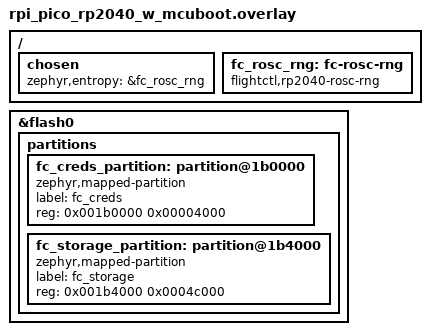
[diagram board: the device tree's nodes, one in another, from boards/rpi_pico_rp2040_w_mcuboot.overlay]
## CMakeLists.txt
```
# flightctl-mcu on Zephyr: the agent core, the Zephyr port and a small
# application. Built with zephyr/build.sh.
cmake_minimum_required(VERSION 3.20)
find_package(Zephyr REQUIRED HINTS $ENV{ZEPHYR_BASE})
project(flightctl_mcu)
# For mbedTLS too: it includes fc-mbedtls-user.h (prj.conf).
zephyr_include_directories(include)

set(ROOT ${CMAKE_CURRENT_LIST_DIR}/..)

# WAMR (third_party/fetch-wamr.sh): fast interpreter only, as in the other
# builds.
enable_language(ASM)
set(WAMR_BUILD_PLATFORM "zephyr")
if(CONFIG_ARCH_POSIX)
    if(CMAKE_HOST_SYSTEM_PROCESSOR MATCHES "^(arm64|aarch64)")
        set(WAMR_BUILD_TARGET "AARCH64")
    else()
        set(WAMR_BUILD_TARGET "X86_64")
    endif()
elseif(CONFIG_CPU_CORTEX_M0PLUS OR CONFIG_CPU_CORTEX_M0)
    set(WAMR_BUILD_TARGET "THUMBV6M")
elseif(CONFIG_CPU_CORTEX_M)
    set(WAMR_BUILD_TARGET "THUMBV7EM")
elseif(CONFIG_XTENSA)
    set(WAMR_BUILD_TARGET "XTENSA")
else()
    message(FATAL_ERROR "flightctl-mcu: no WAMR target for this board yet")
endif()
set(WAMR_BUILD_INTERP 1)
set(WAMR_BUILD_FAST_INTERP 1)
set(WAMR_BUILD_AOT 0)
set(WAMR_BUILD_JIT 0)
set(WAMR_BUILD_LIBC_BUILTIN 0)
set(WAMR_BUILD_LIBC_WASI 0)
set(WAMR_BUILD_SIMD 0)
set(WAMR_BUILD_REF_TYPES 0)
set(WAMR_ROOT_DIR ${ROOT}/third_party/wamr)
include(${WAMR_ROOT_DIR}/build-scripts/runtime_lib.cmake)

# detools (third_party/fetch-detools.sh): firmware deltas, as in the other
# builds (CMakeLists.txt at the root).
set(DETOOLS ${ROOT}/third_party/detools/c)
set(DETOOLS_SRCS ${DETOOLS}/detools.c ${DETOOLS}/heatshrink/heatshrink_decoder.c)

target_sources(app PRIVATE
    src/main.c
    ${ROOT}/port/zephyr/fc_port_zephyr.c
    ${ROOT}/port/zephyr/fc_net_zephyr.c
    ${ROOT}/core/src/fc_agent.c
    ${ROOT}/core/src/fc_http.c
    ${ROOT}/core/src/fc_identity.c
    ${ROOT}/core/src/fc_oci.c
    ${ROOT}/core/src/fc_apps.c
    ${ROOT}/core/src/fc_delta.c
    ${ROOT}/core/third_party/cjson/cJSON.c
    ${DETOOLS_SRCS}
    ${WAMR_RUNTIME_LIB_SOURCE})
if(CONFIG_FC_ENTROPY_RP2_ROSC)
    target_sources(app PRIVATE ${ROOT}/port/zephyr/fc_entropy_rp2.c)
endif()
# Infineon's WiFi driver (the Pico W's) keeps 20 packet buffers. Zephyr 4.5
# made them 2400 bytes each, 16 KB more than a board with 264 KB of RAM can
# give: 1600, what they were up to Zephyr 4.3 and what the board ran with, is
# an Ethernet frame and the chip's header.
if(CONFIG_WIFI_AIROC)
    zephyr_compile_definitions(AIROC_WIFI_PACKET_POOL_SIZE=1600)
endif()
# Raspberry Pi Pico boards: the USB console's conveniences.
if(CONFIG_SOC_FAMILY_RPI_PICO)
    target_sources(app PRIVATE src/board_rp2.c)
endif()
# The C heap is the port's unless the build keeps Zephyr's.
if(NOT CONFIG_COMMON_LIBC_MALLOC)
    target_sources(app PRIVATE ${ROOT}/port/zephyr/fc_heap_zephyr.c)
endif()
target_include_directories(app PRIVATE
    ${ROOT}/core/include ${ROOT}/core/src ${ROOT}/core/third_party/cjson ${ROOT}/port/zephyr
    ${DETOOLS} ${DETOOLS}/heatshrink)
# WAMR 2.4.5's Zephyr port includes <autoconf.h> and <version.h>, which Zephyr
# generates under zephyr/ and no longer puts on the include path as they are.
target_include_directories(app PRIVATE ${ZEPHYR_BINARY_DIR}/include/generated/zephyr)
target_compile_definitions(app PRIVATE
    CJSON_NESTING_LIMIT=32
    DETOOLS_CONFIG_FILE_IO=0 DETOOLS_CONFIG_COMPRESSION_NONE=0 DETOOLS_CONFIG_COMPRESSION_LZMA=0
    DETOOLS_CONFIG_COMPRESSION_CRLE=0 HEATSHRINK_DYNAMIC_ALLOC=1)
if(CONFIG_FC_AGENT_STACK_SIZE)
    target_compile_definitions(app PRIVATE FC_AGENT_STACK_SIZE=${CONFIG_FC_AGENT_STACK_SIZE})
endif()
set_source_files_properties(${DETOOLS_SRCS} PROPERTIES
    COMPILE_DEFINITIONS "malloc=fc_delta_alloc;free=fc_delta_free"
    COMPILE_OPTIONS "-w;-fwrapv")
```

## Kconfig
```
# flightctl-mcu application options.

config FC_SNTP_SERVER
	string "SNTP server the device takes the time from"
	default "pool.ntp.org"

config FC_HEAP_SIZE
	int "Size of the C heap (malloc), in bytes"
	default 163840
	help
	  Everything the agent allocates: TLS sessions, JSON documents, WASM
	  modules and their memory. The device reports how much of it is free.

config FC_AGENT_STACK_SIZE
	int "Stack of each of the agent's two threads, in bytes (0: the core's default)"
	default 0
	help
	  The core asks for 24 KB on a microcontroller. A board short of RAM can
	  give less once it has measured what the threads use (CONFIG_INIT_STACKS
	  and, on the Pico, the console's stack report).

config FC_ENTROPY_RP2_ROSC
	bool "Entropy from the RP2040's ring oscillator"
	depends on SOC_SERIES_RP2040
	depends on DT_HAS_FLIGHTCTL_RP2040_ROSC_RNG_ENABLED
	default y
	select ENTROPY_HAS_DRIVER
	select ENTROPY_NEEDS_PRNG
	help
	  The RP2040 has no random generator and Zephyr no entropy driver for
	  it. This is one (port/zephyr/fc_entropy_rp2.c), for the node the
	  board overlay adds and chooses as zephyr,entropy: the chip's ring
	  oscillator, from which Zephyr and PSA seed their generators.

config FC_FW_VERSION
	string "Firmware version, logged at boot"
	default "dev"

config FC_OTA_VERIFY_TIMEOUT
	int "Seconds a new firmware has to reach Flight Control before it is given up"
	default 150
	help
	  Counted from the boot into the new image. After it the device
	  restarts and MCUboot puts the previous image back.

config FC_TEST_SERVER_PORT
	int "Test only: force this agent endpoint port (0: off)"
	default 0
	help
	  For the test of the way back: a firmware that cannot reach Flight
	  Control whatever the device was provisioned with.

config FC_FW_PLATFORM
	string "The name of this board's firmware in a release"
	default BOARD
	help
	  A firmware release is an OCI index with an image per platform; the
	  device takes the one whose platform.architecture is this.

config FC_LOG_DEBUG
	bool "Log the agent's debug messages"
	default n

source "Kconfig.zephyr"
```

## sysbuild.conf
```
# Used only by builds with a bootloader (zephyr/build.sh on a board named
# .../mcuboot): MCUboot, two slots swapped with a way back, images signed
# with ECDSA P-256. The key is given by build.sh (.secrets/mcuboot-signing.pem).
SB_CONFIG_BOOTLOADER_MCUBOOT=y
SB_CONFIG_MCUBOOT_MODE_SWAP_USING_MOVE=y
SB_CONFIG_BOOT_SIGNATURE_TYPE_ECDSA_P256=y
```

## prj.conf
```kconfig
# flightctl-mcu on Zephyr: what the agent core needs from the system.
# Board-specific settings are in boards/.

# The core is POSIX: threads with the stack size they ask for, clocks, sleep.
CONFIG_POSIX_API=y
CONFIG_THREAD_STACK_INFO=y
CONFIG_DYNAMIC_THREAD=y
CONFIG_DYNAMIC_THREAD_ALLOC=y
CONFIG_DYNAMIC_THREAD_PREFER_ALLOC=y
CONFIG_MAIN_STACK_SIZE=16384
CONFIG_REBOOT=y
CONFIG_HWINFO=y
# The C heap is the port's (port/zephyr/fc_heap_zephyr.c), which reports how
# much of it is free; its size is CONFIG_FC_HEAP_SIZE.
CONFIG_COMMON_LIBC_MALLOC=n
CONFIG_SYS_HEAP_RUNTIME_STATS=y

# Storage: LittleFS on the fc_storage partition (port/zephyr).
CONFIG_FLASH=y
CONFIG_FLASH_MAP=y
CONFIG_FILE_SYSTEM=y
CONFIG_FILE_SYSTEM_LITTLEFS=y

# Network: TCP sockets, DNS, and SNTP for the time certificates are checked
# against.
CONFIG_NETWORKING=y
CONFIG_NET_IPV4=y
CONFIG_NET_IPV6=n
# One interface and the router DHCP gives: no table of static routes (new in
# Zephyr 4.5, and on by default).
CONFIG_NET_IPV4_ROUTE=n
CONFIG_NET_TCP=y
CONFIG_NET_UDP=y
CONFIG_NET_SOCKETS=y
# The agent keeps two connections to Flight Control and opens a third to the
# registry for an app or a firmware; DHCP and DNS have theirs. Zephyr's
# default of four in all refuses the third.
CONFIG_NET_MAX_CONN=10
CONFIG_NET_MAX_CONTEXTS=10
CONFIG_DNS_RESOLVER=y
# The agent's two threads may both look the server up at the same time.
CONFIG_DNS_NUM_CONCUR_QUERIES=3
CONFIG_SNTP=y

# mbedTLS 4.1, as in the other builds: TLS 1.3 with ECDSA P-256 keys, X.509
# and PKCS#10 requests. Its cryptography is PSA's (TF-PSA-Crypto), chosen
# below by what TLS 1.3 and the agent take from it. RSA only for a device key
# in hardware, which the core can make.
CONFIG_PSA_CRYPTO=y
CONFIG_MBEDTLS=y
CONFIG_MBEDTLS_BUILTIN=y
CONFIG_MBEDTLS_SSL_PROTO_TLS1_2=y
CONFIG_MBEDTLS_SSL_PROTO_TLS1_3=y
CONFIG_MBEDTLS_SSL_TLS1_3_KEY_EXCHANGE_MODE_EPHEMERAL_ENABLED=y
CONFIG_MBEDTLS_KEY_EXCHANGE_ECDHE_ECDSA_ENABLED=y
CONFIG_MBEDTLS_KEY_EXCHANGE_ECDHE_RSA_ENABLED=y
CONFIG_MBEDTLS_PSA_CRYPTO_C=y
# The key exchange, the signatures, HKDF, the two AEAD ciphers, the hashes.
CONFIG_PSA_WANT_ALG_ECDH=y
CONFIG_PSA_WANT_ALG_ECDSA=y
CONFIG_PSA_WANT_ALG_DETERMINISTIC_ECDSA=y
CONFIG_PSA_WANT_ALG_HKDF=y
CONFIG_PSA_WANT_ALG_HKDF_EXTRACT=y
CONFIG_PSA_WANT_ALG_HKDF_EXPAND=y
CONFIG_PSA_WANT_ALG_HMAC=y
CONFIG_PSA_WANT_ALG_SHA_256=y
CONFIG_PSA_WANT_ALG_SHA_384=y
CONFIG_PSA_WANT_ALG_GCM=y
CONFIG_PSA_WANT_ALG_CHACHA20_POLY1305=y
CONFIG_PSA_WANT_ALG_TLS12_PRF=y
CONFIG_PSA_WANT_ECC_SECP_R1_256=y
CONFIG_PSA_WANT_ECC_SECP_R1_384=y
CONFIG_PSA_WANT_ECC_MONTGOMERY_255=y
CONFIG_PSA_WANT_KEY_TYPE_AES=y
CONFIG_PSA_WANT_KEY_TYPE_CHACHA20=y
CONFIG_PSA_WANT_KEY_TYPE_HMAC=y
CONFIG_PSA_WANT_KEY_TYPE_ECC_PUBLIC_KEY=y
CONFIG_PSA_WANT_KEY_TYPE_ECC_KEY_PAIR_IMPORT=y
CONFIG_PSA_WANT_KEY_TYPE_ECC_KEY_PAIR_EXPORT=y
CONFIG_PSA_WANT_KEY_TYPE_ECC_KEY_PAIR_GENERATE=y
CONFIG_PSA_WANT_KEY_TYPE_ECC_KEY_PAIR_DERIVE=y
CONFIG_PSA_WANT_ALG_RSA_PKCS1V15_SIGN=y
CONFIG_PSA_WANT_ALG_RSA_PSS=y
CONFIG_PSA_WANT_KEY_TYPE_RSA_PUBLIC_KEY=y
CONFIG_PSA_WANT_KEY_TYPE_RSA_KEY_PAIR_IMPORT=y
CONFIG_PSA_WANT_KEY_TYPE_RSA_KEY_PAIR_EXPORT=y
CONFIG_PSA_WANT_KEY_TYPE_RSA_KEY_PAIR_GENERATE=y
# PSA's random generator: mbedTLS's own (entropy gathered, then a DRBG), fed
# by Zephyr's entropy driver.
CONFIG_MBEDTLS_PSA_CRYPTO_LEGACY_RNG=y
CONFIG_MBEDTLS_CTR_DRBG_C=y
CONFIG_MBEDTLS_HMAC_DRBG_C=y
CONFIG_MBEDTLS_PEM_PARSE_C=y
CONFIG_MBEDTLS_PEM_WRITE_C=y
CONFIG_MBEDTLS_PK_PARSE_C=y
CONFIG_MBEDTLS_PK_WRITE_C=y
CONFIG_MBEDTLS_X509_CRT_PARSE_C=y
CONFIG_MBEDTLS_X509_CSR_WRITE_C=y
CONFIG_MBEDTLS_X509_CSR_PARSE_C=y
CONFIG_MBEDTLS_SSL_SERVER_NAME_INDICATION=y
CONFIG_MBEDTLS_HAVE_TIME_DATE=y
# A TLS connection keeps a buffer for each direction. Records from the server
# can be 16 KB; what the agent sends goes out in records of 4 KB, as in the
# ESP-IDF build: 12 KB less per connection.
CONFIG_MBEDTLS_SSL_IN_CONTENT_LEN=16384
CONFIG_MBEDTLS_SSL_OUT_CONTENT_LEN=4096
# mbedTLS allocates from the C heap, like everything else here: its PSA key
# slots too (static ones cost 38 KB of RAM, sized for the largest RSA key).
CONFIG_MBEDTLS_ENABLE_HEAP=n
CONFIG_MBEDTLS_PSA_STATIC_KEY_SLOTS=n
# The AES tables in flash, not RAM (9 KB).
CONFIG_MBEDTLS_AES_ROM_TABLES=y
CONFIG_MBEDTLS_USER_CONFIG_FILE="fc-mbedtls-user.h"
CONFIG_ENTROPY_GENERATOR=y
```

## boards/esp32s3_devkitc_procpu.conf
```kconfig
# ESP32-S3-DevKitC (board esp32s3_devkitc/esp32s3/procpu): Xtensa LX7, 512 KB
# of RAM, 8 MB of flash, WiFi in the chip. Built with sysbuild
# (zephyr/build.sh does it), which is how Zephyr starts this board: MCUboot,
# then the application, signed, in the first slot.

CONFIG_WIFI=y
CONFIG_NET_MGMT=y
CONFIG_NET_MGMT_EVENT=y
CONFIG_NET_DHCPV4=y
# Where several access points carry the network: the strongest, not the
# first one heard. And back by itself after a drop.
CONFIG_ESP32_WIFI_STA_SCAN_ALL=y
CONFIG_ESP32_WIFI_STA_RECONNECT=y

# Firmware updates into the second slot.
CONFIG_STREAM_FLASH=y
CONFIG_IMG_MANAGER=y
CONFIG_MCUBOOT_IMG_MANAGER=y
CONFIG_IMG_ERASE_PROGRESSIVELY=y

# Zephyr says what a fatal error was before the port restarts the board
# (fc_port_zephyr.c); the minimal log only costs its messages.
CONFIG_LOG=y
CONFIG_LOG_MODE_MINIMAL=y
CONFIG_LOG_DEFAULT_LEVEL=1
CONFIG_THREAD_NAME=y

# Memory. Zephyr gives this chip's first core 372 KB of its RAM for data. The
# agent's threads get 16 KB of stack each instead of the core's 24 KB (they
# use 4.2 KB on the Pico W; Xtensa's register windows take more). The kernel
# heap is 96 KB: the WiFi driver takes 37 KB of it, and thread stacks come
# from the rest (the two agent threads, an app thread of 8 KB). The C heap,
# 128 KB instead of the default 160 KB, makes room for it.
CONFIG_FC_AGENT_STACK_SIZE=16384
CONFIG_HEAP_MEM_POOL_SIZE=98304
CONFIG_FC_HEAP_SIZE=131072
```

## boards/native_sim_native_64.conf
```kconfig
# native_sim: the agent as a Linux process. Zephyr's kernel, POSIX layer, file
# system and mbedTLS are real; the network is the host's, through its sockets.
CONFIG_NET_DRIVERS=y
CONFIG_NET_SOCKETS_OFFLOAD=y
CONFIG_NET_NATIVE_OFFLOADED_SOCKETS=y
CONFIG_ETH_NATIVE_TAP=n
CONFIG_NET_L2_ETHERNET=n
# Seeded from the host's /dev/urandom at each start.
CONFIG_FAKE_ENTROPY_NATIVE_SIM=y
CONFIG_FAKE_ENTROPY_NATIVE_SIM_SEED_BY_DEFAULT=y
# The flash is a file (--flash=PATH): the storage and credentials survive a
# restart.
CONFIG_FLASH_SIMULATOR=y
# A 64-bit host's frames: thread stacks (from the kernel heap) and the C
# heap are sized for that, not for a microcontroller.
CONFIG_HEAP_MEM_POOL_SIZE=2097152
CONFIG_FC_HEAP_SIZE=4194304
```

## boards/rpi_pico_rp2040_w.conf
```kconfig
# Raspberry Pi Pico W: RP2040 (Cortex-M0+, 264 KB of RAM, 2 MB of flash) and
# a CYW43439 for WiFi. Also read for the board started by MCUboot
# (rpi_pico/rp2040/w/mcuboot, which adds rpi_pico_rp2040_w_mcuboot.conf).
CONFIG_WIFI=y
CONFIG_NET_MGMT=y
CONFIG_NET_MGMT_EVENT=y
CONFIG_NET_DHCPV4=y

# Randomness. The RP2040 has no random generator and Zephyr 4.3 no entropy
# driver for it. TLS and the device key take their entropy from the chip's
# ring oscillator (CONFIG_FC_ENTROPY_RP2_ROSC, on by default here). The rest
# of Zephyr (TCP sequence numbers, DNS query ids) uses the test generator,
# which is predictable.
CONFIG_MBEDTLS_ENTROPY_POLL_ZEPHYR=n
CONFIG_TEST_RANDOM_GENERATOR=y

# Zephyr says what a fatal error was before the port restarts the board
# (fc_port_zephyr.c); the minimal log only costs its messages.
CONFIG_LOG=y
CONFIG_LOG_MODE_MINIMAL=y
CONFIG_LOG_DEFAULT_LEVEL=1
# The Cortex-M0+ has no memory protection: a marker at the end of each stack
# is checked instead, so that an overflow is reported, not suffered.
CONFIG_STACK_SENTINEL=y
CONFIG_THREAD_NAME=y

# LittleFS writes whole flash pages (256 bytes). Zephyr 4.3.2 dropped writes
# of less than a page on this chip; third_party/patches fixes that, and this
# stays as it was tried.
CONFIG_FS_LITTLEFS_PROG_SIZE=256
CONFIG_FS_LITTLEFS_CACHE_SIZE=256

# Memory. Measured on the board (CONFIG_INIT_STACKS): the agent's threads
# use 4.2 KB of stack with their TLS connections up, the main thread 3 KB;
# they get 10 KB and 8 KB instead of the 24 KB and 16 KB of roomier boards.
CONFIG_FC_AGENT_STACK_SIZE=10240
CONFIG_MAIN_STACK_SIZE=8192
# What is left of the 264 KB after 106 KB of static data (with the console on
# USB and the log): the kernel heap, which thread stacks come from (the two
# agent threads, an app thread of 8 KB) after the WiFi driver and USB have
# taken 14 KB of it; and the C heap.
CONFIG_HEAP_MEM_POOL_SIZE=46080
CONFIG_FC_HEAP_SIZE=112640
```

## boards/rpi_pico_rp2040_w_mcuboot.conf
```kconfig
# Raspberry Pi Pico W started by MCUboot (board rpi_pico/rp2040/w/mcuboot,
# built with sysbuild: zephyr/build.sh does it): firmware updates into the
# second slot. The rest of the board's configuration is
# rpi_pico_rp2040_w.conf, which sysbuild.cmake adds.
CONFIG_STREAM_FLASH=y
CONFIG_IMG_MANAGER=y
CONFIG_MCUBOOT_IMG_MANAGER=y
# The slot is erased sector by sector as the image arrives: erasing 832 KB at
# once keeps interrupts off for seconds.
CONFIG_IMG_ERASE_PROGRESSIVELY=y
# What a release's index calls this board (platform.architecture).
CONFIG_FC_FW_PLATFORM="rpi_pico_w"
# What Zephyr gives the Pico W and forgets for this variant of it: the
# WiFi chip (the default is another one, with other firmware).
CONFIG_CYW43439=y
```

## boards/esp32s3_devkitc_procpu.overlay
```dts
/*
 * ESP32-S3-DevKitC (8 MB of flash), started by MCUboot: Zephyr's layout for
 * this board (MCUboot in the first 64 KB, two slots of 2880 KB), with its
 * storage partition, 192 KB, split into the credentials and the agent's
 * storage as on the other boards.
 */

/delete-node/ &storage_partition;

&flash0 {
	partitions {
		fc_creds_partition: partition@7b0000 {
			compatible = "zephyr,mapped-partition";
			label = "fc_creds";
			reg = <0x007b0000 0x00004000>;
		};

		fc_storage_partition: partition@7b4000 {
			compatible = "zephyr,mapped-partition";
			label = "fc_storage";
			reg = <0x007b4000 0x0002c000>;
		};
	};
};

&wifi {
	status = "okay";
};

/* The chip's random generator: Zephyr's entropy device, and PSA's source. */
&trng0 {
	status = "okay";
};
```

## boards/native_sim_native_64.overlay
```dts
/*
 * native_sim's 2 MB of simulated flash: Zephyr's own partitions fill the
 * first MB; ours go in the second.
 */
&flash0 {
	partitions {
		fc_creds_partition: partition@100000 {
			compatible = "zephyr,mapped-partition";
			label = "fc_creds";
			reg = <0x00100000 0x00004000>;
		};
		fc_storage_partition: partition@104000 {
			compatible = "zephyr,mapped-partition";
			label = "fc_storage";
			reg = <0x00104000 0x000fc000>;
		};
	};
};
```

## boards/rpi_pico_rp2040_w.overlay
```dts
/*
 * The Pico's 2 MB of flash: the application, then the credentials and the
 * storage in the last 320 KB (where Zephyr's layout for MCUboot on this board
 * puts its storage partition).
 */
/delete-node/ &code_partition;

&flash0 {
	partitions {
		code_partition: partition@100 {
			label = "code-partition";
			reg = <0x00000100 0x001aff00>;
			read-only;
		};
		fc_creds_partition: partition@1b0000 {
			label = "fc_creds";
			reg = <0x001b0000 0x00004000>;
		};
		fc_storage_partition: partition@1b4000 {
			label = "fc_storage";
			reg = <0x001b4000 0x0004c000>;
		};
	};
};
```

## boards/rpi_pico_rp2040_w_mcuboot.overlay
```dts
/*
 * The Pico W with MCUboot: Zephyr's layout for this board (MCUboot in the
 * first 64 KB, two slots of 832 KB), with its storage partition, the last
 * 320 KB, split into the credentials and the agent's storage as in the build
 * without MCUboot.
 */
/delete-node/ &storage_partition;

&flash0 {
	partitions {
		fc_creds_partition: partition@1b0000 {
			compatible = "zephyr,mapped-partition";
			label = "fc_creds";
			reg = <0x001b0000 0x00004000>;
		};
		fc_storage_partition: partition@1b4000 {
			compatible = "zephyr,mapped-partition";
			label = "fc_storage";
			reg = <0x001b4000 0x0004c000>;
		};
	};
};

/ {
	chosen {
		zephyr,entropy = &fc_rosc_rng;
	};

	/* The ring oscillator as the entropy device (port/zephyr/fc_entropy_rp2.c). */
	fc_rosc_rng: fc-rosc-rng {
		compatible = "flightctl,rp2040-rosc-rng";
		status = "okay";
	};
};
```

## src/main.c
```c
/*
 * flightctl-mcu on Zephyr: credentials from the fc_creds partition, the
 * time from SNTP, then the Flight Control agent.
 */
#include <stdio.h>
#include <stdlib.h>
#include <string.h>
#include <time.h>

#include <zephyr/kernel.h>
#include <zephyr/net/sntp.h>
#include <zephyr/storage/flash_map.h>
#include <zephyr/sys/byteorder.h>

#include "cJSON.h"
#include "fc_agent.h"
#include "fc_port.h"
#include "fc_port_zephyr.h"
#include "wasm_export.h"

/* The fc_creds partition, written by deploy/provision.py --format zephyr:
 * "FCC1", the length of what follows (32 bits, little-endian), then a JSON
 * object with the fields of the ESP-IDF firmware's fc_creds: server_host,
 * server_port, ca, enroll_crt, enroll_key, signing_pub, labels. */
#define CREDS_MAGIC "FCC1"
#define CREDS_MAX   (12 * 1024)

static cJSON *load_creds(void)
{
    const struct flash_area *fa;
    if (flash_area_open(PARTITION_ID(fc_creds_partition), &fa) != 0) {
        return NULL;
    }
    uint8_t hdr[8];
    cJSON *creds = NULL;
    if (flash_area_read(fa, 0, hdr, sizeof(hdr)) == 0 && memcmp(hdr, CREDS_MAGIC, 4) == 0) {
        uint32_t len = sys_get_le32(hdr + 4);
        char *json = len <= CREDS_MAX && len + sizeof(hdr) <= fa->fa_size ? malloc(len + 1) : NULL;
        if (json != NULL && flash_area_read(fa, sizeof(hdr), json, len) == 0) {
            json[len] = '\0';
            creds = cJSON_Parse(json);
        }
        free(json);
    }
    flash_area_close(fa);
    return creds;
}

static const char *str(const cJSON *creds, const char *name)
{
    const char *v = cJSON_GetStringValue(cJSON_GetObjectItem(creds, name));
    return v != NULL && v[0] != '\0' ? v : NULL;
}

/* Certificates are checked against the clock, and a device knows no time. */
#ifdef CONFIG_ARCH_POSIX
#include "native_rtc.h"

/* native_sim: the simulated real-time clock starts at the host's time. */
static void wait_for_time(void)
{
    uint64_t us = native_rtc_gettime_us(RTC_CLOCK_REALTIME);
    struct timespec ts = {.tv_sec = (time_t)(us / 1000000), .tv_nsec = (long)(us % 1000000) * 1000};
    clock_settime(CLOCK_REALTIME, &ts);
}
#else
static void wait_for_time(void)
{
    for (;;) {
        struct sntp_time t;
        if (sntp_simple(CONFIG_FC_SNTP_SERVER, 5000, &t) == 0) {
            struct timespec ts = {.tv_sec = (time_t)t.seconds};
            clock_settime(CLOCK_REALTIME, &ts);
            return;
        }
        fc_port_log(FC_LOG_WARN, "waiting for the time from %s...", CONFIG_FC_SNTP_SERVER);
        k_sleep(K_SECONDS(5));
    }
}
#endif

#ifdef CONFIG_WIFI
#include <zephyr/net/net_if.h>
#include <zephyr/net/net_mgmt.h>
#include <zephyr/net/wifi_mgmt.h>

/* Where several access points carry the network, the Pico W's chip may join a
 * far one (Infineon's driver takes no access point's address, and telling the
 * chip to prefer the strongest changed nothing): there, name lookups and
 * handshakes time out. A weak join is given up for another one, a few times.
 * Espressif's driver scans every channel and joins the strongest
 * (CONFIG_ESP32_WIFI_STA_SCAN_ALL, in the board's file). */
#define WIFI_GOOD_DBM (-60)
#define WIFI_JOINS 5

static K_SEM_DEFINE(s_ip_up, 0, 1);
static struct net_mgmt_event_callback s_ip_cb;

static void on_ip(struct net_mgmt_event_callback *cb, uint64_t event, struct net_if *iface)
{
    if (event == NET_EVENT_IPV4_ADDR_ADD) {
        k_sem_give(&s_ip_up);
    }
}

/* Joins the network in the credentials (wifi_ssid, wifi_pass) and waits for
 * an address. */
static void wifi_up(const cJSON *creds)
{
    const char *ssid = str(creds, "wifi_ssid");
    const char *pass = str(creds, "wifi_pass");
    if (ssid == NULL) {
        fc_port_log(FC_LOG_ERROR, "no WiFi network in the credentials (provision.py --wifi-ssid)");
        k_sleep(K_FOREVER);
    }
    struct net_if *iface = net_if_get_default();
    net_mgmt_init_event_callback(&s_ip_cb, on_ip, NET_EVENT_IPV4_ADDR_ADD);
    net_mgmt_add_event_callback(&s_ip_cb);
    struct wifi_connect_req_params p = {
        .ssid = (const uint8_t *)ssid,
        .ssid_length = (uint8_t)strlen(ssid),
        .psk = (const uint8_t *)pass,
        .psk_length = pass != NULL ? (uint8_t)strlen(pass) : 0,
        .security = pass != NULL ? WIFI_SECURITY_TYPE_PSK : WIFI_SECURITY_TYPE_NONE,
        .channel = WIFI_CHANNEL_ANY,
        .band = WIFI_FREQ_BAND_2_4_GHZ,
        .mfp = WIFI_MFP_OPTIONAL,
    };
    int joins = 0;
    for (;;) {
        fc_port_log(FC_LOG_INFO, "WiFi: joining \"%s\"", ssid);
        k_sem_reset(&s_ip_up);
        if (net_mgmt(NET_REQUEST_WIFI_CONNECT, iface, &p, sizeof(p)) == 0) {
            struct wifi_iface_status st = {0};
            int known = net_mgmt(NET_REQUEST_WIFI_IFACE_STATUS, iface, &st, sizeof(st)) == 0;
            /* Infineon's driver has joined when the request returns; others
             * (Espressif's) join after it, and choose the access point
             * themselves. */
            if (IS_ENABLED(CONFIG_WIFI_AIROC) && known && st.rssi < WIFI_GOOD_DBM && ++joins < WIFI_JOINS) {
                fc_port_log(FC_LOG_INFO, "WiFi: access point ..:%02x:%02x is weak (%d dBm), looking for a nearer one",
                            st.bssid[4], st.bssid[5], st.rssi);
                net_mgmt(NET_REQUEST_WIFI_DISCONNECT, iface, NULL, 0);
                k_sleep(K_SECONDS(1));
                continue;
            }
            if (k_sem_take(&s_ip_up, K_SECONDS(30)) == 0) {
                known = net_mgmt(NET_REQUEST_WIFI_IFACE_STATUS, iface, &st, sizeof(st)) == 0;
                if (known) {
                    fc_port_log(FC_LOG_INFO, "WiFi: connected (channel %d, %d dBm, access point ..:%02x:%02x)",
                                st.channel, st.rssi, st.bssid[4], st.bssid[5]);
                } else {
                    fc_port_log(FC_LOG_INFO, "WiFi: connected");
                }
                return;
            }
            net_mgmt(NET_REQUEST_WIFI_DISCONNECT, iface, NULL, 0);
        }
        fc_port_log(FC_LOG_WARN, "WiFi: no connection yet, trying again");
        k_sleep(K_SECONDS(5));
    }
}
#endif

/* Simulated hardware for WASM apps, as on the host: a temperature that swings
 * 30..46 C over two minutes, a 40 C threshold, an LED printed on change. */
static int32_t sim_temp_mc(wasm_exec_env_t env)
{
    long t = (long)(k_uptime_get() / 1000) % 120;
    return 30000 + (int32_t)(t < 60 ? t : 120 - t) * 266;
}

static int32_t sim_threshold_mc(wasm_exec_env_t env)
{
    return 40000;
}

static void sim_led(wasm_exec_env_t env, int32_t r, int32_t g, int32_t b)
{
    static int32_t last = -1;
    int32_t v = (r << 16) | (g << 8) | b;
    if (v != last) {
        printk("LED r=%d g=%d b=%d\n", (int)r, (int)g, (int)b);
        last = v;
    }
}

static NativeSymbol s_natives[] = {
    {"temp_mc", (void *)sim_temp_mc, "()i", NULL},
    {"threshold_mc", (void *)sim_threshold_mc, "()i", NULL},
    {"led", (void *)sim_led, "(iii)", NULL},
};

/* Nothing can be done, and maybe no one was watching when it was first
 * said: say it again every few seconds. */
static void stop(const char *why)
{
    for (;;) {
        fc_port_log(FC_LOG_ERROR, "%s", why);
        k_sleep(K_SECONDS(10));
    }
}

int main(void)
{
    fc_port_log(FC_LOG_INFO, "flightctl-mcu %s on Zephyr, board %s", CONFIG_FC_FW_VERSION, CONFIG_BOARD_TARGET);
    if (fc_port_zephyr_init() != 0) {
        stop("cannot mount the storage (the fc_storage partition)");
    }
    cJSON *creds = load_creds();
    const char *host = str(creds, "server_host");
    const cJSON *port = cJSON_GetObjectItem(creds, "server_port");
    if (host == NULL || str(creds, "ca") == NULL || str(creds, "enroll_crt") == NULL ||
        str(creds, "enroll_key") == NULL) {
        stop("no credentials: write the fc_creds partition (deploy/provision.py --format zephyr)");
    }
    /* {"k": "v", ...} to the {k, v, ..., NULL} the agent takes */
    static const char *labels[33];
    int n = 0;
    const cJSON *l;
    cJSON_ArrayForEach(l, cJSON_GetObjectItem(creds, "labels")) {
        if (n < 30 && cJSON_IsString(l)) {
            labels[n++] = l->string;
            labels[n++] = l->valuestring;
        }
    }

#ifdef CONFIG_WIFI
    wifi_up(creds);
#endif
    wait_for_time();
    size_t heap, heap_free, heap_min, kheap, kheap_free;
    fc_heap_stats(&heap, &heap_free, &heap_min);
    fc_kernel_heap_stats(&kheap, &kheap_free);
    fc_port_log(FC_LOG_INFO, "memory: heap %u of %u bytes free, for thread stacks %u of %u", (unsigned)heap_free,
                (unsigned)heap, (unsigned)kheap_free, (unsigned)kheap);
    fc_agent_config_t cfg = {
        .server_host = host,
        .server_port = CONFIG_FC_TEST_SERVER_PORT != 0 ? CONFIG_FC_TEST_SERVER_PORT
                       : cJSON_IsNumber(port)           ? port->valueint
                                                        : 8443,
        .ca_pem = str(creds, "ca"),
        .enrollment_cert_pem = str(creds, "enroll_crt"),
        .enrollment_key_pem = str(creds, "enroll_key"),
        .signing_pub_pem = str(creds, "signing_pub"),
        .labels = labels,
        .agent_version = "flightctl-mcu/0.1.0",
        .status_interval_s = 60,
        .ota_verify_timeout_s = CONFIG_FC_OTA_VERIFY_TIMEOUT,
        .wasm_natives = s_natives,
        .wasm_natives_count = sizeof(s_natives) / sizeof(s_natives[0]),
    };
    fc_agent_run(&cfg);
    stop("the agent stopped");
    return 1;
}
```

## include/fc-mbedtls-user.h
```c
/* Added to Zephyr's mbedTLS configuration (CONFIG_MBEDTLS_USER_CONFIG_FILE). */

/* The agent logs TLS failures by name (mbedtls_strerror); Zephyr builds the
 * error strings only with mbedTLS's debug output. */
#define MBEDTLS_ERROR_C

/* On the RP2040 the entropy comes from the port (fc_entropy_rp2.c), not from
 * Zephyr's entropy API, which has no driver there. */
#if defined(CONFIG_FC_ENTROPY_RP2_ROSC)
#undef MBEDTLS_NO_DEFAULT_ENTROPY_SOURCES
#define MBEDTLS_ENTROPY_HARDWARE_ALT
#endif

/* A TLS connection keeps a buffer for each direction. Records from the
 * server can be 16 KB; what the agent sends goes out in records of 4 KB, as
 * in the ESP-IDF build: 12 KB less per connection. */
#undef MBEDTLS_SSL_OUT_CONTENT_LEN
#define MBEDTLS_SSL_OUT_CONTENT_LEN 4096
```

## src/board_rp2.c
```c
/*
 * Raspberry Pi Pico boards with the console on USB (west build -S
 * cdc-acm-console), for development:
 * - the boot waits a few seconds for a terminal to open the port, so that
 *   the first messages are not lost;
 * - setting the port to 1200 baud restarts the board in its USB bootloader,
 *   ready for a new UF2, as firmware built with the Pico SDK does
 *   (stty -f /dev/cu.usbmodemXXXX 1200); 2400 baud restarts the firmware.
 */
#include <zephyr/device.h>
#include <zephyr/devicetree.h>
#include <zephyr/drivers/uart.h>
#include <zephyr/init.h>
#include <zephyr/kernel.h>
#include <zephyr/sys/reboot.h>

#include <pico/bootrom.h>

#if DT_NODE_HAS_COMPAT(DT_CHOSEN(zephyr_console), zephyr_cdc_acm_uart)

#define CONSOLE DEVICE_DT_GET(DT_CHOSEN(zephyr_console))

static int wait_for_terminal(void)
{
    for (int i = 0; i < 80; i++) { /* 8 s at most */
        uint32_t dtr = 0, baud = 0;
        /* Also here, before anything else runs: a firmware that fails at
         * every boot can still be replaced. */
        if (uart_line_ctrl_get(CONSOLE, UART_LINE_CTRL_BAUD_RATE, &baud) == 0 && baud == 1200) {
            reset_usb_boot(0, 0);
        }
        if (uart_line_ctrl_get(CONSOLE, UART_LINE_CTRL_DTR, &dtr) == 0 && dtr != 0) {
            k_sleep(K_MSEC(1500)); /* the terminal has opened the port, not yet started to read */
            break;
        }
        k_sleep(K_MSEC(100));
    }
    return 0;
}
SYS_INIT(wait_for_terminal, APPLICATION, 0);

#ifdef CONFIG_INIT_STACKS
/* How much of each thread's stack has ever been used: what tells whether a
 * stack can be smaller on a board with little RAM. */
static void stack_line(const struct k_thread *t, void *arg)
{
    size_t unused = 0;
    if (k_thread_stack_space_get(t, &unused) == 0) {
        const char *name = k_thread_name_get((k_tid_t)t);
        printk("stack %-12s %5u of %5u used\n", name != NULL && name[0] != '\0' ? name : "(pthread)",
               (unsigned)(t->stack_info.size - unused), (unsigned)t->stack_info.size);
    }
}
#endif

static void bootloader_watch(void *a, void *b, void *c)
{
    for (int i = 0;; i++) {
        uint32_t baud = 0;
        if (uart_line_ctrl_get(CONSOLE, UART_LINE_CTRL_BAUD_RATE, &baud) == 0 && baud == 1200) {
            reset_usb_boot(0, 0);
        }
        if (baud == 2400) { /* and 2400 baud just restarts it */
            sys_reboot(SYS_REBOOT_COLD);
        }
#ifdef CONFIG_INIT_STACKS
        if (i % 60 == 59) { /* every 30 s */
            k_thread_foreach(stack_line, NULL);
        }
#endif
        k_sleep(K_MSEC(500));
    }
}
K_THREAD_DEFINE(fc_bootloader_watch, 2048, bootloader_watch, NULL, NULL, NULL, K_LOWEST_APPLICATION_THREAD_PRIO, 0, 0);

#endif
```
